# AU301LDF51 register map
File version: 1.0
Registers are 32-bit, access per field, reset 0x0 unless marked. A register's access mark holds for its fields unless they carry their own. Offsets are from the block's base; [hi:lo] are bit positions.

## CMM — CMM_APB_REG peripheral interface
Base 0x10010000
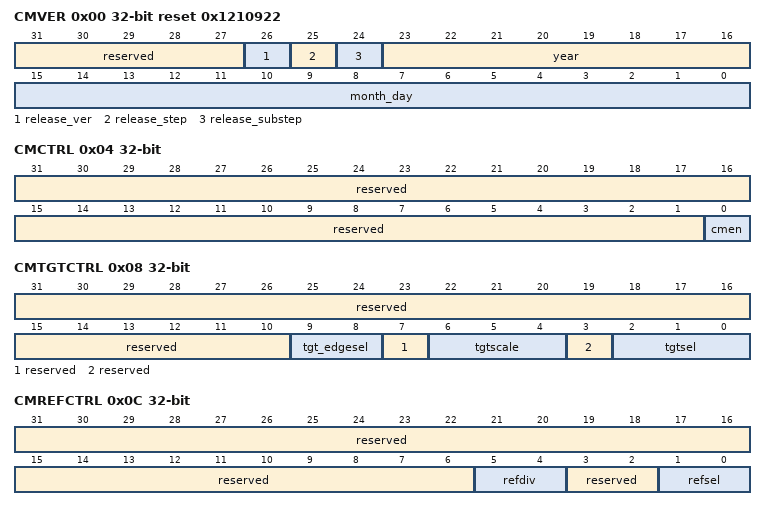
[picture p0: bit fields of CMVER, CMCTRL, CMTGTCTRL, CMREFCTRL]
0x00 CMVER ro reset 0x1210922 — CMM Version，CMM版本信息寄存器。
  [31:27] reserved — 保留。
  [26] release_ver — 版本信息。
  [25] release_step — 版本信息。
  [24] release_substep — 版本信息。
  [23:16] year — 年。
  [15:0] month_day — 月日。
0x04 CMCTRL — CMM Control，CMM控制寄存器。
  [31:1] reserved ro — 保留。
  [0] cmen rw — CMM使能。 0：不使能； 1：使能。
0x08 CMTGTCTRL — CMM Target Clock Control，CMM目标时钟控制寄存器。
  [31:10] reserved ro — 保留。
  [9:8] tgt_edgesel rw — CMM 目标时钟有效沿选择。 00：上升沿； 01：下降沿； 10：双沿； 11：无有效沿。
  [7] reserved ro — 保留。
  [6:4] tgtscale rw — CMM 目标时钟分频系数，偶数倍占空比50%分频，CMM使用分频后的时钟作为被监控对象。 000：不分频； 001：32分频； 010：128分频； 011：1024分频； 100：8192分频； 其他：8192分频。
  [3] reserved ro — 保留。
  [2:0] tgtsel rw — CMM 目标时钟源选择。 000：目标时钟源0，clk_losc； 001：目标时钟源1，clk_hosc； 010：目标时钟源2，clk_xtal； 011：目标时钟源3，clk_hs； 100：目标时钟源4，clk_ls； 101：目标时钟源5，暂无； 110：目标时钟源6，暂无； 111：目标时钟源7，暂无。
0x0C CMREFCTRL — CMM Reference Clock Control，CMM参考时钟控制寄存器。
  [31:6] reserved ro — 保留。
  [5:4] refdiv rw — CMM 参考时钟分频系数，CMM使用分频后的时钟作为监控参考。 00：不分频； 01：4分频； 10：8分频； 11：32分频。
  [3:2] reserved ro — 保留。
  [1:0] refsel rw — CMM 参考时钟源选择。 00：参考时钟源0，clk_losc； 01：参考时钟源1，clk_hosc； 10：参考时钟源2，clk_xtal； 11：参考时钟源3，clk_hs。
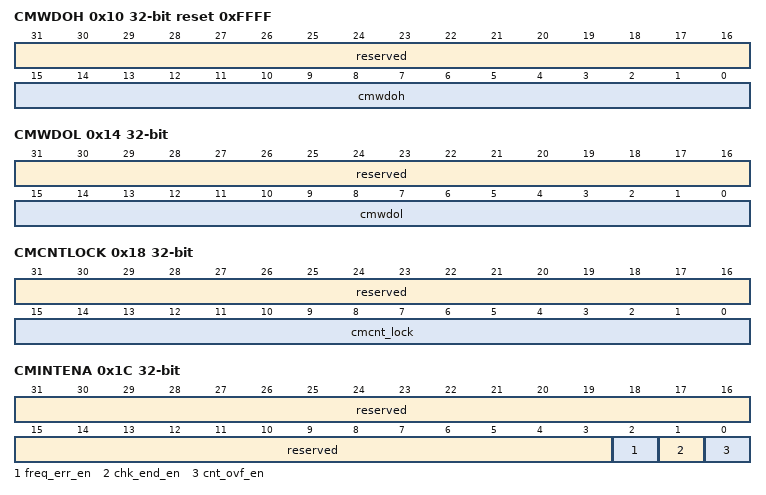
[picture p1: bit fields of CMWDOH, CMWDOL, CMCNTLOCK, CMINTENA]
0x10 CMWDOH reset 0xFFFF — CMM Check Window High，CMM检查窗口上限寄存器。
  [31:16] reserved ro — 保留。
  [15:0] cmwdoh rw — CMM 检查窗口上界限，CMCNT大于该值说明频率错误。
0x14 CMWDOL — CMM Check Window Low，CMM检查窗口下限寄存器。
  [31:16] reserved ro — 保留。
  [15:0] cmwdol rw — CMM 检查窗口下界限，CMCNT小于该值说明频率错误。
0x18 CMCNTLOCK ro — CMM Count Locked Value，CMM计数锁存值寄存器。
  [31:16] reserved — 保留。
  [15:0] cmcnt_lock — CMM 内部计数器计数锁存值。
0x1C CMINTENA — CMM Interrupt Enable，CMM中断使能寄存器。
  [31:3] reserved ro — 保留。
  [2] freq_err_en rw — CMM 频率错误中断使能。不使能时，即屏蔽相应的中断状态，不影响相应的原始中断。若全部不使能，CMM不会上报中断给CPU。 0：不使能； 1：使能。
  [1] chk_end_en rw — CMM 检测结束中断使能。 0：不使能； 1：使能。
  [0] cnt_ovf_en rw — CMM 计数溢出中断使能。 0：不使能； 1：使能。
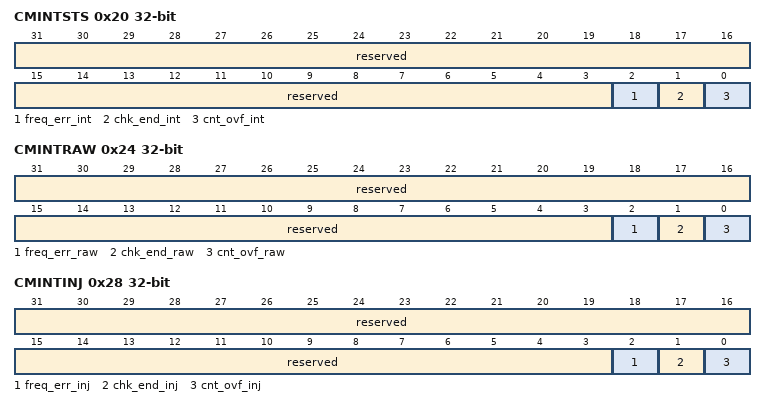
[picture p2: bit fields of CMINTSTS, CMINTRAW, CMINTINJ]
0x20 CMINTSTS ro — CMM Interrupt Status，CMM中断状态寄存器。
  [31:3] reserved — 保留。
  [2] freq_err_int — CMM 频率错误中断状态。 0：无中断； 1：有中断。
  [1] chk_end_int — CMM 检测结束中断状态。 0：无中断； 1：有中断。
  [0] cnt_ovf_int — CMM 计数溢出中断状态。 0：无中断； 1：有中断。
0x24 CMINTRAW — CMM Raw Interrupt，CMM原始中断寄存器。
  [31:3] reserved ro — 保留。
  [2] freq_err_raw rw write-clears — CMM 频率错误原始中断。当CMCTRL[cmen]为1时，才可能产生此中断。 0：无原始中断； 1：有原始中断。写1清除中断。
  [1] chk_end_raw rw write-clears — CMM 检测结束中断原始中断。当CMCTRL[cmen]为1时，才可能产生此中断。 0：无原始中断； 1：有原始中断。写1清除中断。
  [0] cnt_ovf_raw rw write-clears — CMM 计数溢出中断原始中断。当CMCTRL[cmen]为1时，才可能产生此中断。 0：无原始中断； 1：有原始中断。写1清除中断。
0x28 CMINTINJ — CMM Interrupt Injection，CMM中断注入寄存器。
  [31:3] reserved ro — 保留。
  [2] freq_err_inj rw write-1-clears — CMM 频率错误中断注入。 0：不注入； 1：注入。
  [1] chk_end_inj rw write-1-clears — CMM 检测结束中断注入。 0：不注入； 1：注入。
  [0] cnt_ovf_inj rw write-1-clears — CMM 计数溢出中断注入。 0：不注入； 1：注入。

## CRC — CRC_CFG peripheral interface
Base 0x14800000
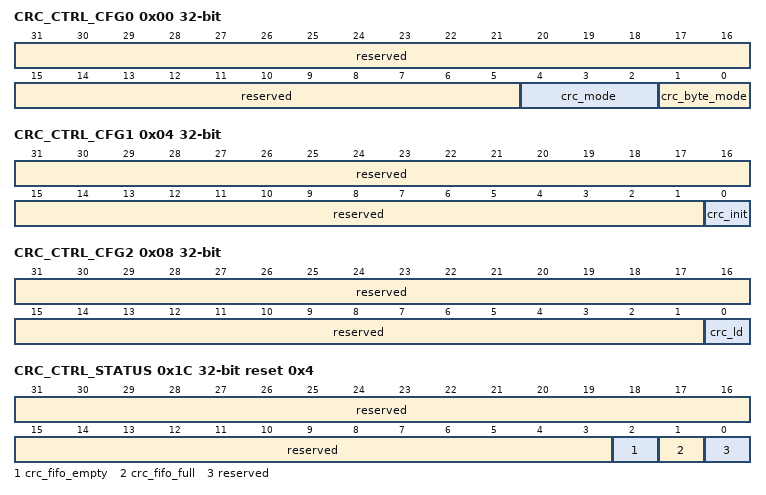
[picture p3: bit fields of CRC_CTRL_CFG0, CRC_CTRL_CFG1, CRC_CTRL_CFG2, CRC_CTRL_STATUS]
0x00 CRC_CTRL_CFG0 — CRC控制寄存器0,用于选择CRC算法及数据有效位。
  [31:5] reserved ro — 保留
  [4:2] crc_mode rw — CRC算法选择。 00x：CRC8_07； 010：CRC16_8005； 011：CRC16_1021； 10x：CRC32_04c11d87； 其他：保留。 X代表0或者1。
  [1:0] crc_byte_mode rw — 数据有效字节选择。 00：低8bit有效； 01：低16bit有效； 10：低24bit有效（reserved）； 11：32bit有效。
0x04 CRC_CTRL_CFG1 — CRC控制寄存器1。
  [31:1] reserved ro — 保留
  [0] crc_init rw write-1-clears — CRC初始化信号，高有效，为单周期脉冲信号，相当于CRC模块的软复位。
0x08 CRC_CTRL_CFG2 — CRC控制寄存器2。
  [31:1] reserved ro — 保留
  [0] crc_ld rw write-1-clears — CRC期望输出值加载信号，高有效，单周期脉冲。当crc_ld有效时，系统将对CRC进行初始值加载（从CRC_CHECK_IN加载到CRC_OUT）。
0x0C CNT_MAX rw — 总线反压计数器计数最大值寄存器。
  [31:0] cnt_max — 总线反压计数器计数最大值。
0x10 CRC_CHECK_IN rw — LOAD 功能配置期望输出值寄存器。
  [31:0] crc_check_in — LOAD功能配置期望输出值。
0x14 CRC_DATA_IN rw — CRC 数据输入寄存器。
  [31:0] crc_data_in — 需要计算的CRC数据。
0x18 CRC_OUT ro — CRC 计算结果寄存器。
  [31:0] crc_out — crc计算结果寄存器，不足位补零。
0x1C CRC_CTRL_STATUS ro reset 0x4 — CRC 状态寄存器。
  [31:3] reserved — 保留
  [2] crc_fifo_empty — FIFO空标志位。 0：无效； 1：有效。
  [1] crc_fifo_full — FIFO满标志位。 0：无效； 1：有效。
  [0] reserved — 保留。
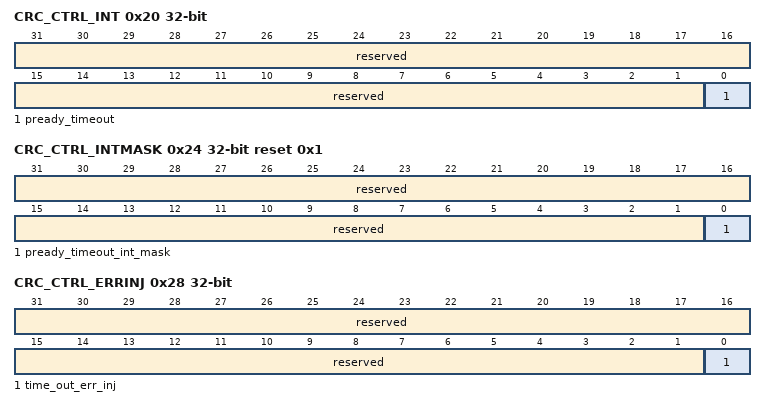
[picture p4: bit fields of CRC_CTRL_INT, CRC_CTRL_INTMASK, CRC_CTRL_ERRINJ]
0x20 CRC_CTRL_INT — 总线反压超时中断寄存器。
  [31:1] reserved ro — 保留
  [0] pready_timeout rw write-1-clears — pready反压超时中断。 0：无效； 1：有效。 向此寄存器写 1 可以清除该中断。
0x24 CRC_CTRL_INTMASK reset 0x1 — 中断屏蔽寄存器。
  [31:1] reserved ro — 保留
  [0] pready_timeout_int_mask rw — pready_timeout中断屏蔽。 0：不屏蔽中断； 1：屏蔽中断。
0x28 CRC_CTRL_ERRINJ — 中断错误注入寄存器，向此寄存器写 1 进行错误注入后会软 件触发 pready 反压超时中断。
  [31:1] reserved ro — 保留
  [0] time_out_err_inj rw — pready反压超时源中断错误注入。 0：无错误注入 1：有错误注入
